AUTOSAR XML (schema 4-0-3)
package /ComponentTypes
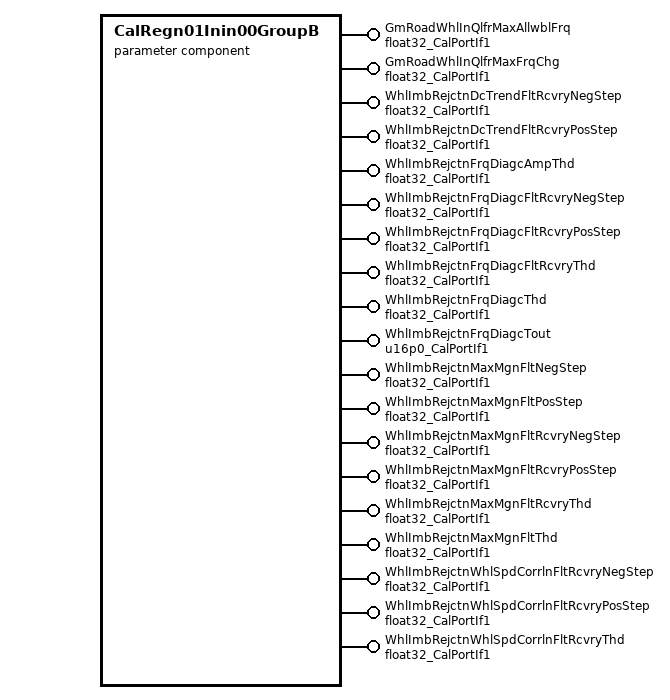
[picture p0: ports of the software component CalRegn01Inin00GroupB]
  parameter sw component type CalRegn01Inin00GroupB
    19 x provide port:
      GmRoadWhlInQlfrMaxAllwblFrq: parameter-provide-com-spec{init-value=55.48, parameter=Val}, provided-interface=float32_CalPortIf1
      GmRoadWhlInQlfrMaxFrqChg: parameter-provide-com-spec{init-value=1.5, parameter=Val}, provided-interface=float32_CalPortIf1
      WhlImbRejctnDcTrendFltRcvryNegStep: parameter-provide-com-spec{init-value=10, parameter=Val}, provided-interface=float32_CalPortIf1
      WhlImbRejctnDcTrendFltRcvryPosStep: parameter-provide-com-spec{init-value=10, parameter=Val}, provided-interface=float32_CalPortIf1
      WhlImbRejctnFrqDiagcAmpThd: parameter-provide-com-spec{init-value=0.0507813, parameter=Val}, provided-interface=float32_CalPortIf1
      WhlImbRejctnFrqDiagcFltRcvryNegStep: parameter-provide-com-spec{init-value=10, parameter=Val}, provided-interface=float32_CalPortIf1
      WhlImbRejctnFrqDiagcFltRcvryPosStep: parameter-provide-com-spec{init-value=10, parameter=Val}, provided-interface=float32_CalPortIf1
      WhlImbRejctnFrqDiagcFltRcvryThd: parameter-provide-com-spec{init-value=100, parameter=Val}, provided-interface=float32_CalPortIf1
      WhlImbRejctnFrqDiagcThd: parameter-provide-com-spec{init-value=0.0117188, parameter=Val}, provided-interface=float32_CalPortIf1
      WhlImbRejctnFrqDiagcTout: parameter-provide-com-spec{init-value=500, parameter=Val}, provided-interface=u16p0_CalPortIf1
      WhlImbRejctnMaxMgnFltNegStep: parameter-provide-com-spec{init-value=10, parameter=Val}, provided-interface=float32_CalPortIf1
      WhlImbRejctnMaxMgnFltPosStep: parameter-provide-com-spec{init-value=10, parameter=Val}, provided-interface=float32_CalPortIf1
      WhlImbRejctnMaxMgnFltRcvryNegStep: parameter-provide-com-spec{init-value=10, parameter=Val}, provided-interface=float32_CalPortIf1
      WhlImbRejctnMaxMgnFltRcvryPosStep: parameter-provide-com-spec{init-value=10, parameter=Val}, provided-interface=float32_CalPortIf1
      WhlImbRejctnMaxMgnFltRcvryThd: parameter-provide-com-spec{init-value=100, parameter=Val}, provided-interface=float32_CalPortIf1
      WhlImbRejctnMaxMgnFltThd: parameter-provide-com-spec{init-value=100, parameter=Val}, provided-interface=float32_CalPortIf1
      WhlImbRejctnWhlSpdCorrlnFltRcvryNegStep: parameter-provide-com-spec{init-value=10, parameter=Val}, provided-interface=float32_CalPortIf1
      WhlImbRejctnWhlSpdCorrlnFltRcvryPosStep: parameter-provide-com-spec{init-value=10, parameter=Val}, provided-interface=float32_CalPortIf1
      WhlImbRejctnWhlSpdCorrlnFltRcvryThd: parameter-provide-com-spec{init-value=100, parameter=Val}, provided-interface=float32_CalPortIf1
